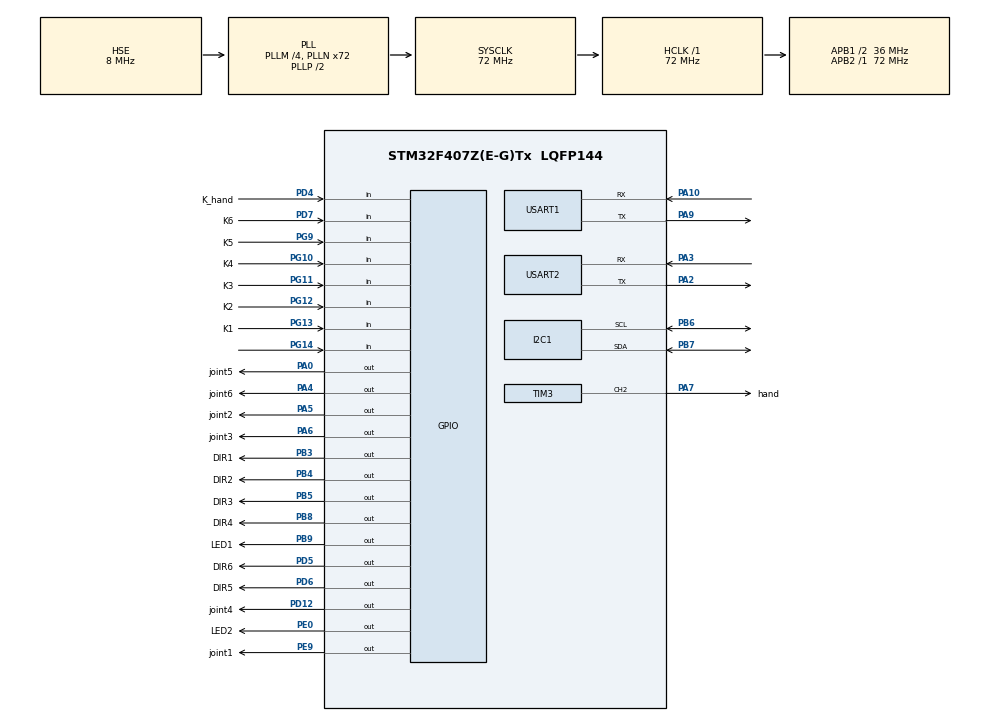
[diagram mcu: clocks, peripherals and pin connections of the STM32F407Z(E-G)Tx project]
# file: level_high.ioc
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I2C1.I2C_Mode=I2C_Fast
Mcu.Family=STM32F4
Mcu.Name=STM32F407Z(E-G)Tx
Mcu.Package=LQFP144
NVIC.PriorityGroup=NVIC_PRIORITYGROUP_4
NVIC.USART1_IRQn=true\:0\:0\:false\:false\:true\:true\:true\:true
NVIC.USART2_IRQn=true\:0\:0\:false\:false\:true\:true\:true\:true
PA0-WKUP.GPIO_Label=joint5
PA0-WKUP.GPIO_PuPd=GPIO_NOPULL
PA0-WKUP.GPIO_Speed=GPIO_SPEED_FREQ_MEDIUM
PA0-WKUP.PinState=GPIO_PIN_SET
PA0-WKUP.Signal=GPIO_Output
PA10.Mode=Asynchronous
PA10.Signal=USART1_RX
PA13.Mode=Serial_Wire
PA13.Signal=SYS_JTMS-SWDIO
PA14.Mode=Serial_Wire
PA14.Signal=SYS_JTCK-SWCLK
PA2.Mode=Asynchronous
PA2.Signal=USART2_TX
PA3.Mode=Asynchronous
PA3.Signal=USART2_RX
PA4.GPIO_Label=joint6
PA4.GPIO_Speed=GPIO_SPEED_FREQ_MEDIUM
PA4.PinState=GPIO_PIN_SET
PA4.Signal=GPIO_Output
PA5.GPIO_Label=joint2
PA5.GPIO_PuPd=GPIO_NOPULL
PA5.GPIO_Speed=GPIO_SPEED_FREQ_MEDIUM
PA5.PinState=GPIO_PIN_SET
PA5.Signal=GPIO_Output
PA6.GPIO_Label=joint3
PA6.GPIO_Speed=GPIO_SPEED_FREQ_MEDIUM
PA6.PinState=GPIO_PIN_SET
PA6.Signal=GPIO_Output
PA7.GPIO_Label=hand
PA7.GPIO_Speed=GPIO_SPEED_FREQ_MEDIUM
PA7.Signal=S_TIM3_CH2
PA9.Mode=Asynchronous
PA9.Signal=USART1_TX
PB3.GPIO_Label=DIR1
PB3.PinState=GPIO_PIN_SET
PB3.Signal=GPIO_Output
PB4.GPIO_Label=DIR2
PB4.PinState=GPIO_PIN_SET
PB4.Signal=GPIO_Output
PB5.GPIO_Label=DIR3
PB5.PinState=GPIO_PIN_SET
PB5.Signal=GPIO_Output
PB6.Mode=I2C
PB6.Signal=I2C1_SCL
PB7.Mode=I2C
PB7.Signal=I2C1_SDA
PB8.GPIO_Label=DIR4
PB8.PinState=GPIO_PIN_SET
PB8.Signal=GPIO_Output
PB9.GPIO_Label=LED1
PB9.PinState=GPIO_PIN_SET
PB9.Signal=GPIO_Output
PD12.GPIO_Label=joint4
PD12.GPIO_Speed=GPIO_SPEED_FREQ_MEDIUM
PD12.PinState=GPIO_PIN_SET
PD12.Signal=GPIO_Output
PD4.GPIO_Label=K_hand
PD4.Signal=GPIO_Input
PD5.GPIO_Label=DIR6
PD5.PinState=GPIO_PIN_SET
PD5.Signal=GPIO_Output
PD6.GPIO_Label=DIR5
PD6.PinState=GPIO_PIN_SET
PD6.Signal=GPIO_Output
PD7.GPIO_Label=K6
PD7.GPIO_PuPd=GPIO_PULLUP
PD7.Signal=GPIO_Input
PE0.GPIO_Label=LED2
PE0.PinState=GPIO_PIN_SET
PE0.Signal=GPIO_Output
PE9.GPIO_Label=joint1
PE9.GPIO_PuPd=GPIO_NOPULL
PE9.GPIO_Speed=GPIO_SPEED_FREQ_MEDIUM
PE9.PinState=GPIO_PIN_SET
PE9.Signal=GPIO_Output
PG10.GPIO_Label=K4
PG10.GPIO_PuPd=GPIO_PULLUP
PG10.Signal=GPIO_Input
PG11.GPIO_Label=K3
PG11.GPIO_PuPd=GPIO_PULLUP
PG11.Signal=GPIO_Input
PG12.GPIO_Label=K2
PG12.GPIO_PuPd=GPIO_PULLUP
PG12.Signal=GPIO_Input
PG13.GPIO_Label=K1
PG13.GPIO_PuPd=GPIO_PULLUP
PG13.Signal=GPIO_Input
PG14.GPIO_PuPd=GPIO_PULLUP
PG14.Signal=GPIO_Input
PG9.GPIO_Label=K5
PG9.GPIO_PuPd=GPIO_PULLUP
PG9.Signal=GPIO_Input
PH0-OSC_IN.Mode=HSE-External-Oscillator
PH0-OSC_IN.Signal=RCC_OSC_IN
PH1-OSC_OUT.Mode=HSE-External-Oscillator
PH1-OSC_OUT.Signal=RCC_OSC_OUT
ProjectManager.HeapSize=0x200
ProjectManager.StackSize=0x400
ProjectManager.TargetToolchain=Makefile
RCC.48MHZClocksFreq_Value=36000000
RCC.AHBFreq_Value=72000000
RCC.APB1CLKDivider=RCC_HCLK_DIV2
RCC.APB1Freq_Value=36000000
RCC.APB1TimFreq_Value=72000000
RCC.APB2Freq_Value=72000000
RCC.APB2TimFreq_Value=72000000
RCC.CortexFreq_Value=72000000
RCC.HCLKFreq_Value=72000000
RCC.HSE_VALUE=8000000
RCC.HSI_VALUE=16000000
RCC.LSE_VALUE=32768
RCC.PLLM=4
RCC.PLLN=72
RCC.PLLSourceVirtual=RCC_PLLSOURCE_HSE
RCC.SYSCLKFreq_VALUE=72000000
RCC.SYSCLKSource=RCC_SYSCLKSOURCE_PLLCLK
RCC.VCOOutputFreq_Value=144000000
SH.S_TIM3_CH2.0=TIM3_CH2,PWM Generation2 CH2
TIM3.Channel-PWM\ Generation2\ CH2=TIM_CHANNEL_2
TIM3.Period=20000
TIM3.Prescaler=72-1
USART1.VirtualMode=VM_ASYNC
USART2.VirtualMode=VM_ASYNC
VP_TIM3_VS_ClockSourceINT.Mode=Internal
board=custom

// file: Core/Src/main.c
/* USER CODE BEGIN Header */
/**
 ******************************************************************************
 * @file           : main.c
 * @brief          : Main program body
 ******************************************************************************
 * @attention
 *
 * Copyright (c) 2025 STMicroelectronics.
 * All rights reserved.
 *
 * This software is licensed under terms that can be found in the LICENSE file
 * in the root directory of this software component.
 * If no LICENSE file comes with this software, it is provided AS-IS.
 *
 ******************************************************************************
 */
/* USER CODE END Header */
#include "main.h"
#include "i2c.h"
#include "tim.h"
#include "usart.h"
#include "gpio.h"

void SystemClock_Config(void);

/* USER CODE BEGIN 0 */
void for_delay_us(uint32_t nus)
{
  uint32_t Delay = nus * 168 / 4;
  do
  {
    __NOP();
  } while (Delay--);
}
void Motor3(void)
{
  HAL_GPIO_TogglePin(joint3_GPIO_Port, joint3_Pin);
}
void Motor2(void)
{
  HAL_GPIO_TogglePin(joint2_GPIO_Port, joint2_Pin);
}
/* USER CODE END 0 */

int main(void)
{

  /* MCU Configuration--------------------------------------------------------*/

  /* Reset of all peripherals, Initializes the Flash interface and the Systick. */
  HAL_Init();

  /* Configure the system clock */
  SystemClock_Config();

  /* Initialize all configured peripherals */
  MX_GPIO_Init();
  MX_USART1_UART_Init();
  MX_I2C1_Init();
  MX_TIM3_Init();
  MX_USART2_UART_Init();

  /* Infinite loop */
  while (1)
  {

    /* USER CODE BEGIN 3 */

    /*:经测试：最好将速度保持在50us一个step以下
    Motor3();
    Motor2();
    for_delay_us(50);
     */
  }
  /* USER CODE END 3 */
}

void SystemClock_Config(void)
{
  RCC_OscInitTypeDef RCC_OscInitStruct = {0};
  RCC_ClkInitTypeDef RCC_ClkInitStruct = {0};

  /** Configure the main internal regulator output voltage
   */
  __HAL_RCC_PWR_CLK_ENABLE();
  __HAL_PWR_VOLTAGESCALING_CONFIG(PWR_REGULATOR_VOLTAGE_SCALE1);

  /** Initializes the RCC Oscillators according to the specified parameters
   * in the RCC_OscInitTypeDef structure.
   */
  RCC_OscInitStruct.OscillatorType = RCC_OSCILLATORTYPE_HSE;
  RCC_OscInitStruct.HSEState = RCC_HSE_ON;
  RCC_OscInitStruct.PLL.PLLState = RCC_PLL_ON;
  RCC_OscInitStruct.PLL.PLLSource = RCC_PLLSOURCE_HSE;
  RCC_OscInitStruct.PLL.PLLM = 4;
  RCC_OscInitStruct.PLL.PLLN = 72;
  RCC_OscInitStruct.PLL.PLLP = RCC_PLLP_DIV2;
  RCC_OscInitStruct.PLL.PLLQ = 4;
  if (HAL_RCC_OscConfig(&RCC_OscInitStruct) != HAL_OK)
  {
    Error_Handler();
  }

  /** Initializes the CPU, AHB and APB buses clocks
   */
  RCC_ClkInitStruct.ClockType = RCC_CLOCKTYPE_HCLK | RCC_CLOCKTYPE_SYSCLK | RCC_CLOCKTYPE_PCLK1 | RCC_CLOCKTYPE_PCLK2;
  RCC_ClkInitStruct.SYSCLKSource = RCC_SYSCLKSOURCE_PLLCLK;
  RCC_ClkInitStruct.AHBCLKDivider = RCC_SYSCLK_DIV1;
  RCC_ClkInitStruct.APB1CLKDivider = RCC_HCLK_DIV2;
  RCC_ClkInitStruct.APB2CLKDivider = RCC_HCLK_DIV1;

  if (HAL_RCC_ClockConfig(&RCC_ClkInitStruct, FLASH_LATENCY_2) != HAL_OK)
  {
    Error_Handler();
  }
}

void Error_Handler(void)
{
  __disable_irq();
  while (1)
  {
  }
}
